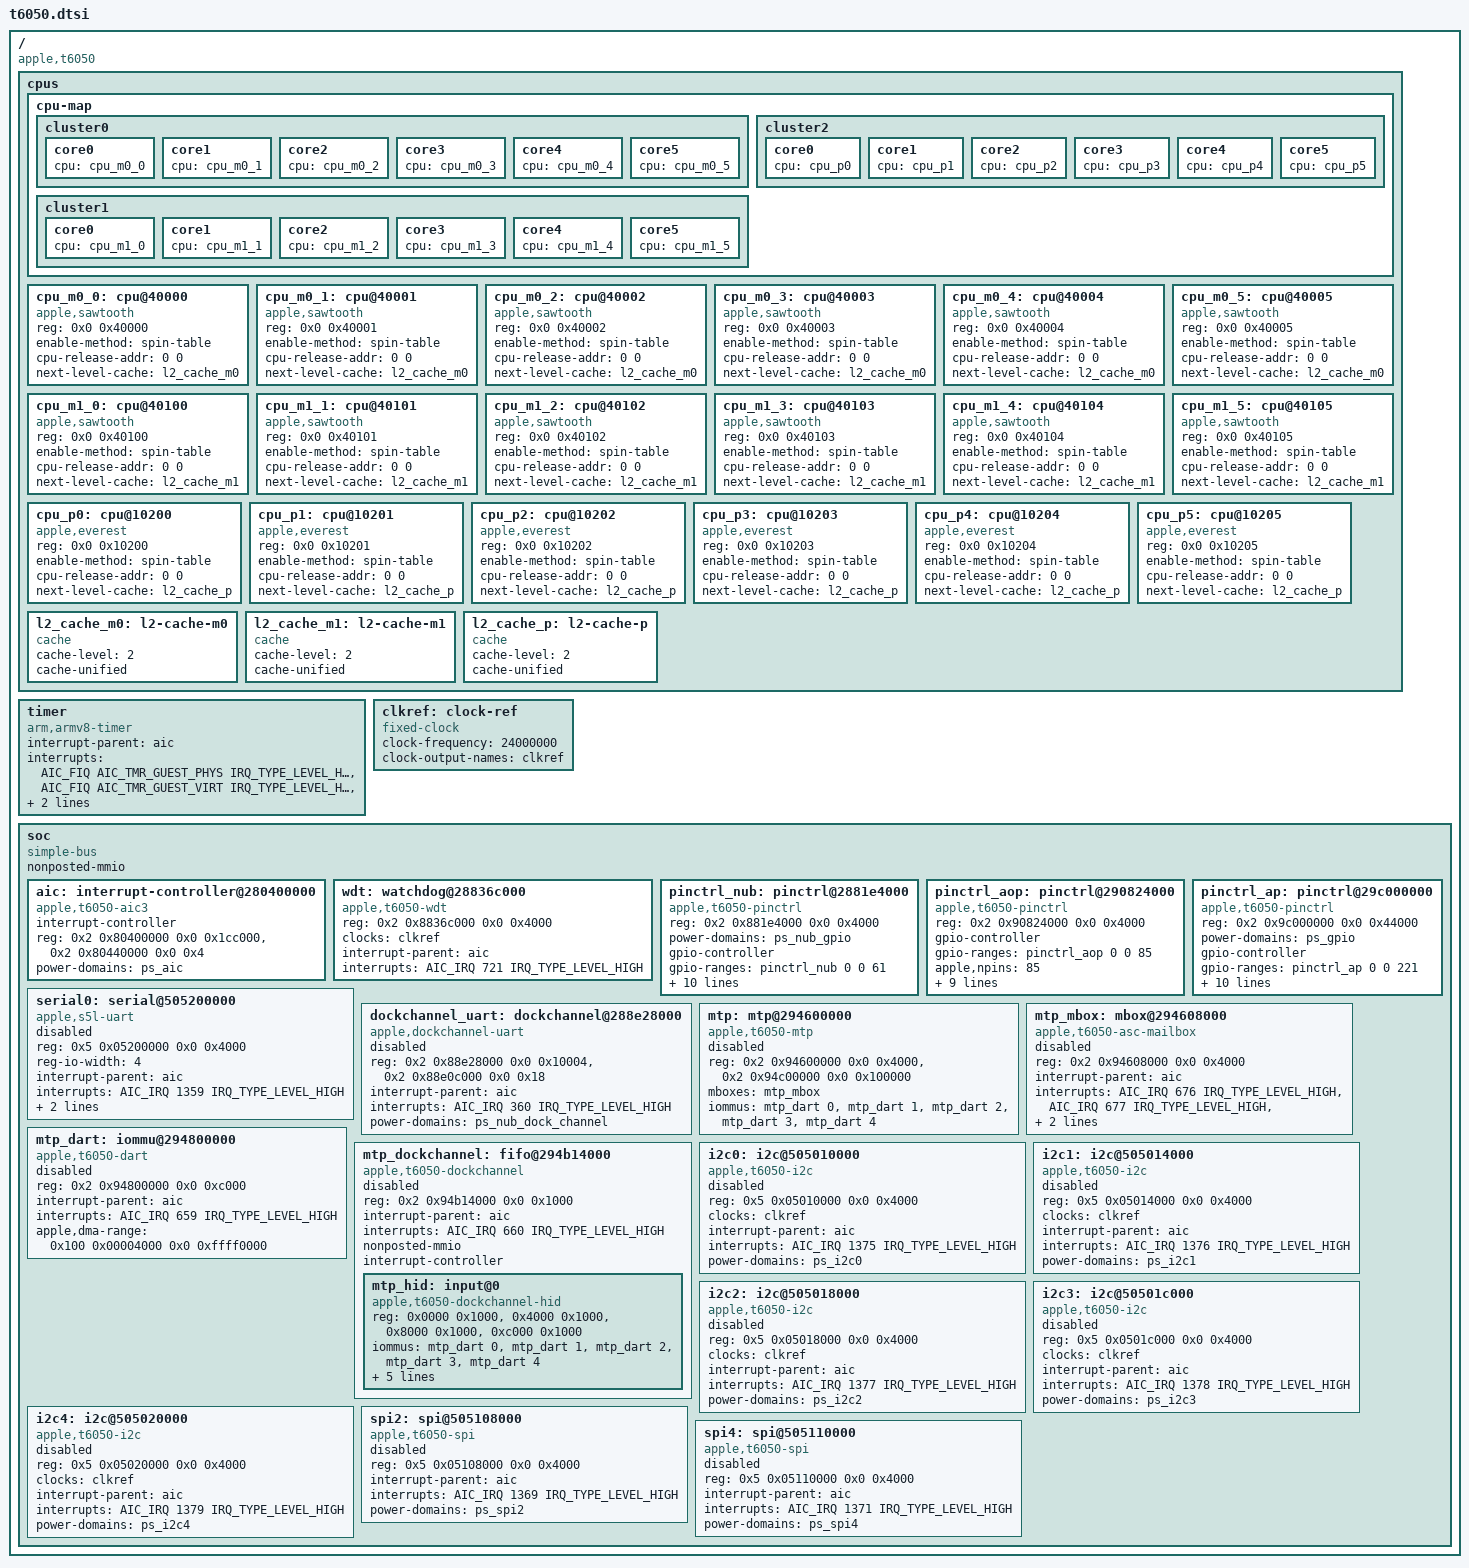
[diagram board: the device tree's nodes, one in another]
// SPDX-License-Identifier: GPL-2.0+ OR MIT
/*
 * Apple T6050 "M5 Pro" SoC (Sotra_S / H17S)
 *
 * Authored for omarchy-m5 Phase 1 bring-up, modeled on
 * arch/arm64/boot/dts/apple/t8132.dtsi (asahi-wip-7.2).
 *
 * Sources (all verified against the real J714s machine, macOS 26.5):
 *   - MMIO addresses + IRQs: on-device IORegistry/ADT dump. ADT reg
 *     values sit 0x2_0000_0000 below the MMIO address (uart0 ADT
 *     0x305200000 -> 0x505200000 = m1n1 EARLY_UART_BASE for T6050).
 *   - CPU topology: 15 cores on J714s (binned SKU) = 2x5 "M-core"
 *     clusters (cpu0-4, cpu6-10) + 1x5 "super" P-core cluster
 *     (cpu12-16); cpu5/cpu11/cpu17 absent. Full SKUs (J716s/J716c)
 *     have 6 per cluster. MPIDR = (cluster_id << 8) | core_id.
 *     ADT compatibles: M-cores "apple,sawtooth", P-cores "apple,everest".
 *   - PMGR: generated from the on-device ADT by scripts/adt2pmgr.py
 *     (see t6050-pmgr.dtsi).
 *
 * Boot CPU is cpu0 (an M-core). Secondary cores currently do NOT start
 * (docs/research/kernel-boot-m5.md §6.1) — boot with maxcpus=1 until the
 * AppleT6050PMGR enableCPUCore sequence is reverse-engineered.
 *
 * Copyright The Asahi Linux Contributors / omarchy-m5 contributors
 */

#include <dt-bindings/interrupt-controller/apple-aic.h>
#include <dt-bindings/interrupt-controller/irq.h>
#include <dt-bindings/pinctrl/apple.h>

/ {
	compatible = "apple,t6050", "apple,arm-platform";

	#address-cells = <2>;
	#size-cells = <2>;

	cpus {
		#address-cells = <2>;
		#size-cells = <0>;

		cpu-map {
			cluster0 {
				core0 { cpu = <&cpu_m0_0>; };
				core1 { cpu = <&cpu_m0_1>; };
				core2 { cpu = <&cpu_m0_2>; };
				core3 { cpu = <&cpu_m0_3>; };
				core4 { cpu = <&cpu_m0_4>; };
				core5 { cpu = <&cpu_m0_5>; };
			};
			cluster1 {
				core0 { cpu = <&cpu_m1_0>; };
				core1 { cpu = <&cpu_m1_1>; };
				core2 { cpu = <&cpu_m1_2>; };
				core3 { cpu = <&cpu_m1_3>; };
				core4 { cpu = <&cpu_m1_4>; };
				core5 { cpu = <&cpu_m1_5>; };
			};
			cluster2 {
				core0 { cpu = <&cpu_p0>; };
				core1 { cpu = <&cpu_p1>; };
				core2 { cpu = <&cpu_p2>; };
				core3 { cpu = <&cpu_p3>; };
				core4 { cpu = <&cpu_p4>; };
				core5 { cpu = <&cpu_p5>; };
			};
		};

		/*
		 * All 18 possible cores are described; boards disable the ones
		 * fused off on binned SKUs (J714s: cpu5, cpu11, cpu17 absent).
		 *
		 * reg is MPIDR_EL1[23:0]. Apple's layout (m1n1 src/midr.h:
		 * MIDR_CORE_TYPE_P = BIT(16), MIDR_CORE_TYPE_M = BIT(18)):
		 *   Aff2 = core type: 0 E, 1 P, 4 M     <- boot core: 0x80040000
		 *   Aff1 = cluster-id from the ADT      (M0 = 0, M1 = 1, P = 2)
		 *   Aff0 = core within the cluster
		 * so the P cluster is 0x10200 + core, NOT 0x40200: the type lives
		 * in Aff2 and is not shared with the M cores. Same scheme as
		 * t6031 (E 0x0, P 0x10100/0x10200).
		 *
		 * Only the boot core (0x40000) is measured; the rest is derived
		 * from the ADT cluster-id/cluster-core-id. m1n1 compares reg with
		 * the MPIDR each started core reports and aborts DT preparation
		 * with "DT CPU %d MPIDR mismatch: <dt> != <hw>", which prints the
		 * real value, so a wrong guess is loud, not silent.
		 */
		cpu_m0_0: cpu@40000 {
			compatible = "apple,sawtooth";
			device_type = "cpu";
			reg = <0x0 0x40000>;
			enable-method = "spin-table";
			cpu-release-addr = <0 0>;
			next-level-cache = <&l2_cache_m0>;
		};
		cpu_m0_1: cpu@40001 {
			compatible = "apple,sawtooth";
			device_type = "cpu";
			reg = <0x0 0x40001>;
			enable-method = "spin-table";
			cpu-release-addr = <0 0>;
			next-level-cache = <&l2_cache_m0>;
		};
		cpu_m0_2: cpu@40002 {
			compatible = "apple,sawtooth";
			device_type = "cpu";
			reg = <0x0 0x40002>;
			enable-method = "spin-table";
			cpu-release-addr = <0 0>;
			next-level-cache = <&l2_cache_m0>;
		};
		cpu_m0_3: cpu@40003 {
			compatible = "apple,sawtooth";
			device_type = "cpu";
			reg = <0x0 0x40003>;
			enable-method = "spin-table";
			cpu-release-addr = <0 0>;
			next-level-cache = <&l2_cache_m0>;
		};
		cpu_m0_4: cpu@40004 {
			compatible = "apple,sawtooth";
			device_type = "cpu";
			reg = <0x0 0x40004>;
			enable-method = "spin-table";
			cpu-release-addr = <0 0>;
			next-level-cache = <&l2_cache_m0>;
		};
		cpu_m0_5: cpu@40005 {
			compatible = "apple,sawtooth";
			device_type = "cpu";
			reg = <0x0 0x40005>;
			enable-method = "spin-table";
			cpu-release-addr = <0 0>;
			next-level-cache = <&l2_cache_m0>;
		};

		cpu_m1_0: cpu@40100 {
			compatible = "apple,sawtooth";
			device_type = "cpu";
			reg = <0x0 0x40100>;
			enable-method = "spin-table";
			cpu-release-addr = <0 0>;
			next-level-cache = <&l2_cache_m1>;
		};
		cpu_m1_1: cpu@40101 {
			compatible = "apple,sawtooth";
			device_type = "cpu";
			reg = <0x0 0x40101>;
			enable-method = "spin-table";
			cpu-release-addr = <0 0>;
			next-level-cache = <&l2_cache_m1>;
		};
		cpu_m1_2: cpu@40102 {
			compatible = "apple,sawtooth";
			device_type = "cpu";
			reg = <0x0 0x40102>;
			enable-method = "spin-table";
			cpu-release-addr = <0 0>;
			next-level-cache = <&l2_cache_m1>;
		};
		cpu_m1_3: cpu@40103 {
			compatible = "apple,sawtooth";
			device_type = "cpu";
			reg = <0x0 0x40103>;
			enable-method = "spin-table";
			cpu-release-addr = <0 0>;
			next-level-cache = <&l2_cache_m1>;
		};
		cpu_m1_4: cpu@40104 {
			compatible = "apple,sawtooth";
			device_type = "cpu";
			reg = <0x0 0x40104>;
			enable-method = "spin-table";
			cpu-release-addr = <0 0>;
			next-level-cache = <&l2_cache_m1>;
		};
		cpu_m1_5: cpu@40105 {
			compatible = "apple,sawtooth";
			device_type = "cpu";
			reg = <0x0 0x40105>;
			enable-method = "spin-table";
			cpu-release-addr = <0 0>;
			next-level-cache = <&l2_cache_m1>;
		};

		cpu_p0: cpu@10200 {
			compatible = "apple,everest";
			device_type = "cpu";
			reg = <0x0 0x10200>;
			enable-method = "spin-table";
			cpu-release-addr = <0 0>;
			next-level-cache = <&l2_cache_p>;
		};
		cpu_p1: cpu@10201 {
			compatible = "apple,everest";
			device_type = "cpu";
			reg = <0x0 0x10201>;
			enable-method = "spin-table";
			cpu-release-addr = <0 0>;
			next-level-cache = <&l2_cache_p>;
		};
		cpu_p2: cpu@10202 {
			compatible = "apple,everest";
			device_type = "cpu";
			reg = <0x0 0x10202>;
			enable-method = "spin-table";
			cpu-release-addr = <0 0>;
			next-level-cache = <&l2_cache_p>;
		};
		cpu_p3: cpu@10203 {
			compatible = "apple,everest";
			device_type = "cpu";
			reg = <0x0 0x10203>;
			enable-method = "spin-table";
			cpu-release-addr = <0 0>;
			next-level-cache = <&l2_cache_p>;
		};
		cpu_p4: cpu@10204 {
			compatible = "apple,everest";
			device_type = "cpu";
			reg = <0x0 0x10204>;
			enable-method = "spin-table";
			cpu-release-addr = <0 0>;
			next-level-cache = <&l2_cache_p>;
		};
		cpu_p5: cpu@10205 {
			compatible = "apple,everest";
			device_type = "cpu";
			reg = <0x0 0x10205>;
			enable-method = "spin-table";
			cpu-release-addr = <0 0>;
			next-level-cache = <&l2_cache_p>;
		};

		l2_cache_m0: l2-cache-m0 {
			compatible = "cache";
			cache-level = <2>;
			cache-unified;
		};
		l2_cache_m1: l2-cache-m1 {
			compatible = "cache";
			cache-level = <2>;
			cache-unified;
		};
		l2_cache_p: l2-cache-p {
			compatible = "cache";
			cache-level = <2>;
			cache-unified;
		};
	};

	timer {
		compatible = "arm,armv8-timer";
		interrupt-parent = <&aic>;
		interrupt-names = "phys", "virt", "hyp-phys", "hyp-virt";
		interrupts = <AIC_FIQ AIC_TMR_GUEST_PHYS IRQ_TYPE_LEVEL_HIGH>,
		             <AIC_FIQ AIC_TMR_GUEST_VIRT IRQ_TYPE_LEVEL_HIGH>,
		             <AIC_FIQ AIC_TMR_HV_PHYS IRQ_TYPE_LEVEL_HIGH>,
		             <AIC_FIQ AIC_TMR_HV_VIRT IRQ_TYPE_LEVEL_HIGH>;
	};

	clkref: clock-ref {
		compatible = "fixed-clock";
		#clock-cells = <0>;
		clock-frequency = <24000000>;
		clock-output-names = "clkref";
	};

	soc: soc {
		compatible = "simple-bus";
		#address-cells = <2>;
		#size-cells = <2>;

		ranges;
		nonposted-mmio;

		/*
		 * AICv3. ADT: 0x80400000 -> MMIO 0x280400000, size 0x1cc000.
		 * The event register sits at aic-iack-offset (0x40000, runtime
		 * ADT) like t8122/t8132. Linux's AICv2/v3 probe requires it as
		 * reg[1]; without it the driver bails before installing any
		 * IRQ/FIQ handler and the kernel runs with no interrupts.
		 */
		aic: interrupt-controller@280400000 {
			compatible = "apple,t6050-aic3", "apple,t8122-aic3";
			#interrupt-cells = <3>;
			interrupt-controller;
			reg = <0x2 0x80400000 0x0 0x1cc000>,
			      <0x2 0x80440000 0x0 0x4>;
			reg-names = "core", "event";
			power-domains = <&ps_aic>;
			/* TODO(adt): PMU FIQ affinities (M-core vs P-core indices) */
		};

		/* ADT: 0x8836c000 -> 0x28836c000, IRQ 0x2d1 = 721 */
		wdt: watchdog@28836c000 {
			compatible = "apple,t6050-wdt", "apple,t8103-wdt";
			reg = <0x2 0x8836c000 0x0 0x4000>;
			clocks = <&clkref>;
			interrupt-parent = <&aic>;
			interrupts = <AIC_IRQ 721 IRQ_TYPE_LEVEL_HIGH>;
		};

		/* ADT: nub-gpio0 0x881e4000 -> 0x2881e4000, 61 pins */
		pinctrl_nub: pinctrl@2881e4000 {
			compatible = "apple,t6050-pinctrl", "apple,t8103-pinctrl";
			reg = <0x2 0x881e4000 0x0 0x4000>;
			power-domains = <&ps_nub_gpio>;

			gpio-controller;
			#gpio-cells = <2>;
			gpio-ranges = <&pinctrl_nub 0 0 61>;
			apple,npins = <61>;

			interrupt-controller;
			#interrupt-cells = <2>;
			interrupt-parent = <&aic>;
			interrupts = <AIC_IRQ 706 IRQ_TYPE_LEVEL_HIGH>,
			             <AIC_IRQ 708 IRQ_TYPE_LEVEL_HIGH>,
			             <AIC_IRQ 710 IRQ_TYPE_LEVEL_HIGH>,
			             <AIC_IRQ 712 IRQ_TYPE_LEVEL_HIGH>,
			             <AIC_IRQ 714 IRQ_TYPE_LEVEL_HIGH>,
			             <AIC_IRQ 716 IRQ_TYPE_LEVEL_HIGH>,
			             <AIC_IRQ 718 IRQ_TYPE_LEVEL_HIGH>;
		};

		/* ADT: aop-gpio0 0x90824000 -> 0x290824000, 85 pins */
		pinctrl_aop: pinctrl@290824000 {
			compatible = "apple,t6050-pinctrl", "apple,t8103-pinctrl";
			reg = <0x2 0x90824000 0x0 0x4000>;

			gpio-controller;
			#gpio-cells = <2>;
			gpio-ranges = <&pinctrl_aop 0 0 85>;
			apple,npins = <85>;

			interrupt-controller;
			#interrupt-cells = <2>;
			interrupt-parent = <&aic>;
			interrupts = <AIC_IRQ 568 IRQ_TYPE_LEVEL_HIGH>,
			             <AIC_IRQ 569 IRQ_TYPE_LEVEL_HIGH>,
			             <AIC_IRQ 570 IRQ_TYPE_LEVEL_HIGH>,
			             <AIC_IRQ 571 IRQ_TYPE_LEVEL_HIGH>,
			             <AIC_IRQ 572 IRQ_TYPE_LEVEL_HIGH>,
			             <AIC_IRQ 573 IRQ_TYPE_LEVEL_HIGH>,
			             <AIC_IRQ 574 IRQ_TYPE_LEVEL_HIGH>;
		};

		/* ADT: gpio0 0x9c000000 -> 0x29c000000, 221 pins */
		pinctrl_ap: pinctrl@29c000000 {
			compatible = "apple,t6050-pinctrl", "apple,t8103-pinctrl";
			reg = <0x2 0x9c000000 0x0 0x44000>;
			power-domains = <&ps_gpio>;

			gpio-controller;
			#gpio-cells = <2>;
			gpio-ranges = <&pinctrl_ap 0 0 221>;
			apple,npins = <221>;

			interrupt-controller;
			#interrupt-cells = <2>;
			interrupt-parent = <&aic>;
			interrupts = <AIC_IRQ 486 IRQ_TYPE_LEVEL_HIGH>,
			             <AIC_IRQ 487 IRQ_TYPE_LEVEL_HIGH>,
			             <AIC_IRQ 488 IRQ_TYPE_LEVEL_HIGH>,
			             <AIC_IRQ 489 IRQ_TYPE_LEVEL_HIGH>,
			             <AIC_IRQ 490 IRQ_TYPE_LEVEL_HIGH>,
			             <AIC_IRQ 491 IRQ_TYPE_LEVEL_HIGH>,
			             <AIC_IRQ 492 IRQ_TYPE_LEVEL_HIGH>;

			/* TODO(adt): pinmux tables for i2c/spi/uart */
		};

		/*
		 * Debug UART. ADT uart0 0x305200000 -> 0x505200000 = m1n1
		 * EARLY_UART_BASE for T6050. IRQ 0x54f = 1359.
		 */
		serial0: serial@505200000 {
			compatible = "apple,s5l-uart";
			reg = <0x5 0x05200000 0x0 0x4000>;
			reg-io-width = <4>;
			interrupt-parent = <&aic>;
			interrupts = <AIC_IRQ 1359 IRQ_TYPE_LEVEL_HIGH>;
			clocks = <&clkref>, <&clkref>;
			clock-names = "uart", "clk_uart_baud0";
			power-domains = <&ps_uart0>;
			status = "disabled";
		};

		/*
		 * Dockchannel UART (USB-C debug). ADT: 0x88e28000 ->
		 * 0x288e28000, IRQ 0x168 = 360. Driver: apple-dockchannel
		 * (downstream in linux-asahi).
		 */
		dockchannel_uart: dockchannel@288e28000 {
			compatible = "apple,dockchannel-uart", "apple,dockchannel";
			reg = <0x2 0x88e28000 0x0 0x10004>,
			      <0x2 0x88e0c000 0x0 0x18>;
			interrupt-parent = <&aic>;
			interrupts = <AIC_IRQ 360 IRQ_TYPE_LEVEL_HIGH>;
			power-domains = <&ps_nub_dock_channel>;
			status = "disabled";
		};

		/*
		 * MTP (Multi-Touch Processor): built-in keyboard + trackpad.
		 * The J714s has NO SPI keyboard: /arm-io/spi2 only has "mesa"
		 * (Touch ID) and spi4 only the panel's "dp855". Input is an RTKit
		 * coprocessor (ADT /arm-io/mtp, "iop,ascwrap-v6") speaking HID over
		 * a DockChannel FIFO pair (/arm-io/dockchannel-mtp/mtp-transport).
		 *
		 * All values from build/adt-runtime-j714s.bin (get_reg() already
		 * translated, raw ADT + 0x2_0000_0000). The raw ADT offsets
		 * (0x94600000/0x94800000/0x94b14000) are identical to T8132 (M4)
		 * and the T8142 (M5) address map, i.e. same IP layout.
		 *
		 *   mtp reg[0]   0x294600000 size 0x88000  -> ASC block (CPU_CONTROL
		 *                at +0x44, mailbox at +0x8000)
		 *   mtp reg[1]   0x294050000 size 0x4000   -> ascwrap-v6 wrapper
		 *                (unused by Linux)
		 *   fw segments  __TEXT 0x294c00000+0x54000, __DATA 0x294c54000+0x6c000
		 *                = MTP SRAM (M2/M3 convention: 1 MiB at B+0xc00000);
		 *                __OS_LOG 0x10004818000+0x3000 (DRAM, iBoot-owned)
		 *   iop-mtp-nub  pre-loaded = 1: iBoot already loaded and started the
		 *                RTKit firmware; Linux only wakes it (rtkit-helper).
		 *   mailbox IRQs ADT [677,676,679,678] = {send-not-empty, send-empty,
		 *                recv-not-empty, recv-empty}; Linux order is ascending.
		 *   dart-mtp     0x294800000 (t8110 DART, m1n1 uses reg[0] as the
		 *                DART base), IRQ 659, sid-count 16, mapper SID 0,
		 *                ADT remap = {1,2,3,4}: requestor SIDs 1-4 alias to
		 *                SID 0, expressed with the in-tree multi-SID remap
		 *                (iommus lists every SID; the first one owns the
		 *                TTBR, the rest get TCR.REMAP -> first).
		 *   dockchannel  irq regs 0x294b14000, IRQ 660; FIFO pairs
		 *                rmt-config/rmt-data 0x294b28000/0x294b2c000,
		 *                config/data 0x294b30000/0x294b34000, fifo-size 2048.
		 * No PMGR domain: the T6050 ADT has no MTP_* pmgr device at all
		 * (only NUB_DOCK_CHANNEL, which is the debug dockchannel-uart).
		 */
		mtp: mtp@294600000 {
			compatible = "apple,t6050-mtp", "apple,t6050-rtk-helper-asc4",
				     "apple,mtp", "apple,rtk-helper-asc4";
			reg = <0x2 0x94600000 0x0 0x4000>,
			      <0x2 0x94c00000 0x0 0x100000>;
			reg-names = "asc", "sram";
			mboxes = <&mtp_mbox>;
			iommus = <&mtp_dart 0>, <&mtp_dart 1>, <&mtp_dart 2>,
				 <&mtp_dart 3>, <&mtp_dart 4>;
			#helper-cells = <0>;
			status = "disabled";
		};

		mtp_mbox: mbox@294608000 {
			compatible = "apple,t6050-asc-mailbox", "apple,asc-mailbox-v4";
			reg = <0x2 0x94608000 0x0 0x4000>;
			interrupt-parent = <&aic>;
			interrupts = <AIC_IRQ 676 IRQ_TYPE_LEVEL_HIGH>,
				     <AIC_IRQ 677 IRQ_TYPE_LEVEL_HIGH>,
				     <AIC_IRQ 678 IRQ_TYPE_LEVEL_HIGH>,
				     <AIC_IRQ 679 IRQ_TYPE_LEVEL_HIGH>;
			interrupt-names = "send-empty", "send-not-empty",
					  "recv-empty", "recv-not-empty";
			#mbox-cells = <0>;
			status = "disabled";
		};

		mtp_dart: iommu@294800000 {
			compatible = "apple,t6050-dart", "apple,t8110-dart";
			reg = <0x2 0x94800000 0x0 0xc000>;
			interrupt-parent = <&aic>;
			interrupts = <AIC_IRQ 659 IRQ_TYPE_LEVEL_HIGH>;
			#iommu-cells = <1>;
			/* ADT vm-base 0x10000004000, vm-size 0xffff0000 (same window the
			 * T8140 MTP/USB DARTs use in aurora-silicon/linux). */
			apple,dma-range = <0x100 0x00004000 0x0 0xffff0000>;
			status = "disabled";
		};

		mtp_dockchannel: fifo@294b14000 {
			compatible = "apple,t6050-dockchannel", "apple,dockchannel";
			reg = <0x2 0x94b14000 0x0 0x1000>;
			reg-names = "irq";
			interrupt-parent = <&aic>;
			interrupts = <AIC_IRQ 660 IRQ_TYPE_LEVEL_HIGH>;

			ranges = <0 0x2 0x94b28000 0x10000>;
			nonposted-mmio;
			#address-cells = <1>;
			#size-cells = <1>;

			interrupt-controller;
			#interrupt-cells = <2>;

			status = "disabled";

			mtp_hid: input@0 {
				/* t8132 selects the ring transport in dockchannel-hid */
				compatible = "apple,t6050-dockchannel-hid",
					     "apple,t8132-dockchannel-hid",
					     "apple,dockchannel-hid";
				reg = <0x0000 0x1000>,
				      <0x4000 0x1000>,
				      <0x8000 0x1000>,
				      <0xc000 0x1000>;
				reg-names = "rmt-config", "rmt-data", "config", "data";
				iommus = <&mtp_dart 0>, <&mtp_dart 1>, <&mtp_dart 2>,
					 <&mtp_dart 3>, <&mtp_dart 4>;
				interrupt-parent = <&mtp_dockchannel>;
				interrupts = <2 IRQ_TYPE_LEVEL_HIGH>,
					     <3 IRQ_TYPE_LEVEL_HIGH>;
				interrupt-names = "tx", "rx";
				apple,fifo-size = <0x800>;
				apple,helper-cpu = <&mtp>;
			};
		};

		/* ADT: i2c0-4 at 0x30501{0,4,8,c,20}000 -> 0x50501... */
		i2c0: i2c@505010000 {
			compatible = "apple,t6050-i2c", "apple,t8103-i2c";
			reg = <0x5 0x05010000 0x0 0x4000>;
			clocks = <&clkref>;
			interrupt-parent = <&aic>;
			interrupts = <AIC_IRQ 1375 IRQ_TYPE_LEVEL_HIGH>;
			#address-cells = <0x1>;
			#size-cells = <0x0>;
			power-domains = <&ps_i2c0>;
			status = "disabled";
		};

		i2c1: i2c@505014000 {
			compatible = "apple,t6050-i2c", "apple,t8103-i2c";
			reg = <0x5 0x05014000 0x0 0x4000>;
			clocks = <&clkref>;
			interrupt-parent = <&aic>;
			interrupts = <AIC_IRQ 1376 IRQ_TYPE_LEVEL_HIGH>;
			#address-cells = <0x1>;
			#size-cells = <0x0>;
			power-domains = <&ps_i2c1>;
			status = "disabled";
		};

		i2c2: i2c@505018000 {
			compatible = "apple,t6050-i2c", "apple,t8103-i2c";
			reg = <0x5 0x05018000 0x0 0x4000>;
			clocks = <&clkref>;
			interrupt-parent = <&aic>;
			interrupts = <AIC_IRQ 1377 IRQ_TYPE_LEVEL_HIGH>;
			#address-cells = <0x1>;
			#size-cells = <0x0>;
			power-domains = <&ps_i2c2>;
			status = "disabled";
		};

		i2c3: i2c@50501c000 {
			compatible = "apple,t6050-i2c", "apple,t8103-i2c";
			reg = <0x5 0x0501c000 0x0 0x4000>;
			clocks = <&clkref>;
			interrupt-parent = <&aic>;
			interrupts = <AIC_IRQ 1378 IRQ_TYPE_LEVEL_HIGH>;
			#address-cells = <0x1>;
			#size-cells = <0x0>;
			power-domains = <&ps_i2c3>;
			status = "disabled";
		};

		i2c4: i2c@505020000 {
			compatible = "apple,t6050-i2c", "apple,t8103-i2c";
			reg = <0x5 0x05020000 0x0 0x4000>;
			clocks = <&clkref>;
			interrupt-parent = <&aic>;
			interrupts = <AIC_IRQ 1379 IRQ_TYPE_LEVEL_HIGH>;
			#address-cells = <0x1>;
			#size-cells = <0x0>;
			power-domains = <&ps_i2c4>;
			status = "disabled";
		};

		/*
		 * SPI: ADT spi2 0x305108000 -> 0x505108000 (IRQ 1369, only child
		 * "mesa" = Touch ID), spi4 0x305110000 -> 0x505110000 (IRQ 1371,
		 * only children dp855 + display-temp-sens*). Neither carries the
		 * keyboard/trackpad: those are on the MTP, see mtp@294600000.
		 */
		spi2: spi@505108000 {
			compatible = "apple,t6050-spi", "apple,t8103-spi";
			reg = <0x5 0x05108000 0x0 0x4000>;
			interrupt-parent = <&aic>;
			interrupts = <AIC_IRQ 1369 IRQ_TYPE_LEVEL_HIGH>;
			#address-cells = <1>;
			#size-cells = <0>;
			power-domains = <&ps_spi2>;
			status = "disabled";
		};

		spi4: spi@505110000 {
			compatible = "apple,t6050-spi", "apple,t8103-spi";
			reg = <0x5 0x05110000 0x0 0x4000>;
			interrupt-parent = <&aic>;
			interrupts = <AIC_IRQ 1371 IRQ_TYPE_LEVEL_HIGH>;
			#address-cells = <1>;
			#size-cells = <0>;
			power-domains = <&ps_spi4>;
			status = "disabled";
		};
	};
};

#include "t6050-pmgr.dtsi"
#include "t6050-storage-net.dtsi"
